AUTOSAR XML (schema 4-2-2)
standard types defined: boolean, float32, uint8
package /ASWC
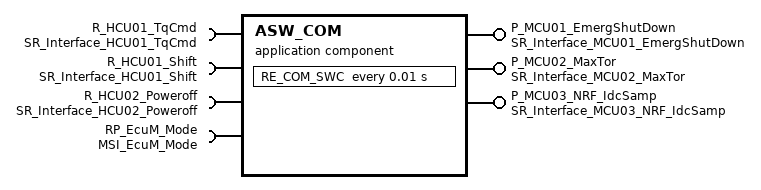
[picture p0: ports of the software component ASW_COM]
  application sw component type ASW_COM
    provide port P_MCU01_EmergShutDown: provided-interface=SR_Interface_MCU01_EmergShutDown
    provide port P_MCU02_MaxTor: provided-interface=SR_Interface_MCU02_MaxTor
    provide port P_MCU03_NRF_IdcSamp: provided-interface=SR_Interface_MCU03_NRF_IdcSamp
    4 x require port:
      R_HCU01_TqCmd: required-interface=SR_Interface_HCU01_TqCmd
      R_HCU01_Shift: required-interface=SR_Interface_HCU01_Shift
      R_HCU02_Poweroff: nonqueued-receiver-com-spec{data-element=DE_HCU02_Poweroff, alive-timeout=0.3, init-value=0}, required-interface=SR_Interface_HCU02_Poweroff
      RP_EcuM_Mode: required-interface=MSI_EcuM_Mode
    behavior IB_ASW_COM
      timing event TE_RE_COM_SWC_10ms: start-on-event=RE_COM_SWC, period=0.01
      data receive error event DREE_R_HCU02_Poweroff: start-on-event=RE_COM_SWC, data=R_HCU02_Poweroff.DE_HCU02_Poweroff
      runnable RE_COM_SWC
        data-read-access-points:
          access VA_READ_HCU01_TqCmd: accessed-variable=R_HCU01_TqCmd.DE_HCU01_TqCmd
          access VA_READ_HCU01_Shift: accessed-variable=R_HCU01_Shift.DE_HCU01_Shift
          access VA_READ_HCU02_Poweroff: accessed-variable=R_HCU02_Poweroff.DE_HCU02_Poweroff
        data-write-access-points:
          access VA_WRITE_MCU01_EmergShutDown: accessed-variable=P_MCU01_EmergShutDown.DE_MCU01_EmergShutDown
          access VA_WRITE_MCU02_MaxTor: accessed-variable=P_MCU02_MaxTor.DE_MCU02_MaxTor
          access VA_WRITE_MCU03_NRF_IdcSamp: accessed-variable=P_MCU03_NRF_IdcSamp.DE_MCU03_NRF_IdcSamp
        mode access point VA_MODE_SLEEP: mode-group=RP_EcuM_Mode.EcuM_Mode
package /COM_Interface
  6 x sender receiver interface:
    SR_Interface_MCU01_EmergShutDown
      data DE_MCU01_EmergShutDown: type=boolean
    SR_Interface_MCU02_MaxTor
      data DE_MCU02_MaxTor: type=float32
    SR_Interface_MCU03_NRF_IdcSamp
      data DE_MCU03_NRF_IdcSamp: type=float32
    SR_Interface_HCU01_TqCmd
      data DE_HCU01_TqCmd: type=float32
    SR_Interface_HCU01_Shift
      data DE_HCU01_Shift: type=uint8
    SR_Interface_HCU02_Poweroff
      data DE_HCU02_Poweroff: type=boolean
  mode switch interface MSI_EcuM_Mode
    mode group EcuM_Mode: type=MDG_EcuM_State
package /DataTypes/ModeDeclarationGroups
  mode declaration group MDG_EcuM_State: initial-mode=RUN
    mode RUN
    mode SLEEP
